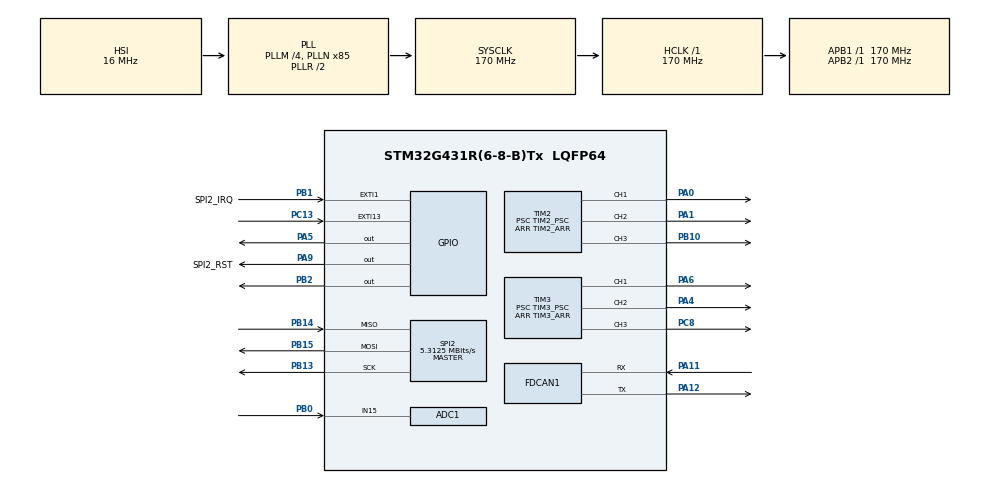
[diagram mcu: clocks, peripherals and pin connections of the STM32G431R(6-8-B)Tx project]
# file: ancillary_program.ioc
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ADC1.Channel-0\#ChannelRegularConversion=ADC_CHANNEL_15
ADC1.ContinuousConvMode=ENABLE
ADC1.EnableInjectedConversion=DISABLE
ADC1.NbrOfConversionFlag=1
ADC1.OffsetNumber-0\#ChannelRegularConversion=ADC_OFFSET_NONE
ADC1.Overrun=ADC_OVR_DATA_OVERWRITTEN
ADC1.Rank-0\#ChannelRegularConversion=1
ADC1.Rank1_Channel=ADC_CHANNEL_15
ADC1.SamplingTime-0\#ChannelRegularConversion=ADC_SAMPLETIME_640CYCLES_5
ADC1.master=1
FDCAN1.CalculateBaudRateNominal=499999
FDCAN1.CalculateTimeBitNominal=2000
FDCAN1.CalculateTimeQuantumNominal=117.64705882352942
FDCAN1.DataPrescaler=2
FDCAN1.DataTimeSeg1=14
FDCAN1.DataTimeSeg2=2
FDCAN1.NominalPrescaler=20
FDCAN1.NominalTimeSeg1=14
FDCAN1.ProtocolException=ENABLE
FDCAN1.StdFiltersNbr=FDCAN_FILTER_COUNT
FDCAN1.TransmitPause=ENABLE
FREERTOS.Tasks01=DefaultTask,24,512,StartDefaultTask,As weak,NULL,Dynamic,NULL,NULL;ArmMotorTask,49,128,StartArmMotorTask,As weak,NULL,Dynamic,NULL,NULL;FdCanTask,41,256,StartFdCanTask,As weak,NULL,Dynamic,NULL,NULL;RfidTask,51,256,StartRfidTask,As weak,NULL,Dynamic,NULL,NULL;MapTask,50,256,StartMapTask,As weak,NULL,Dynamic,NULL,NULL;ArmTask,48,128,StartArmTask,As weak,NULL,Dynamic,NULL,NULL
FREERTOS.configTOTAL_HEAP_SIZE=8192
FREERTOS.configUSE_NEWLIB_REENTRANT=1
Mcu.Family=STM32G4
Mcu.Name=STM32G431R(6-8-B)Tx
Mcu.Package=LQFP64
NUCLEO-G431RB.BUTTON=1
NUCLEO-G431RB.LD1=true
NUCLEO-G431RB.VCP=true
NVIC.EXTI15_10_IRQn=true\:5\:0\:false\:false\:true\:true\:false\:true\:true
NVIC.EXTI1_IRQn=true\:5\:0\:false\:false\:true\:true\:true\:true\:true
NVIC.FDCAN1_IT0_IRQn=true\:5\:0\:false\:false\:true\:true\:true\:true\:true
NVIC.FDCAN1_IT1_IRQn=true\:5\:0\:false\:false\:true\:true\:true\:true\:true
NVIC.PriorityGroup=NVIC_PRIORITYGROUP_4
NVIC.TIM6_DAC_IRQn=true\:15\:0\:false\:false\:true\:false\:false\:true\:true
NVIC.TimeBase=TIM6_DAC_IRQn
NVIC.TimeBaseIP=TIM6
PA0.Signal=S_TIM2_CH1
PA1.Signal=S_TIM2_CH2
PA11.Mode=FDCAN_Activate
PA11.Signal=FDCAN1_RX
PA12.Mode=FDCAN_Activate
PA12.Signal=FDCAN1_TX
PA13.GPIO_Label=T_SWDIO
PA13.Signal=SYS_JTMS-SWDIO
PA14.GPIO_Label=T_SWCLK
PA14.Signal=SYS_JTCK-SWCLK
PA2.Signal=LPUART1_TX
PA3.Signal=LPUART1_RX
PA4.Signal=S_TIM3_CH2
PA5.Signal=GPIO_Output
PA6.Signal=S_TIM3_CH1
PA9.GPIO_Label=SPI2_RST
PA9.Signal=GPIO_Output
PB0.Mode=IN15-Single-Ended
PB0.Signal=ADC1_IN15
PB1.GPIO_Label=SPI2_IRQ
PB1.GPIO_ModeDefaultEXTI=GPIO_MODE_IT_FALLING
PB1.GPIO_PuPd=GPIO_PULLUP
PB1.Signal=GPXTI1
PB10.Signal=S_TIM2_CH3
PB13.Mode=Full_Duplex_Master
PB13.Signal=SPI2_SCK
PB14.Mode=Full_Duplex_Master
PB14.Signal=SPI2_MISO
PB15.Mode=Full_Duplex_Master
PB15.Signal=SPI2_MOSI
PB2.Signal=GPIO_Output
PB3.GPIO_Label=T_SWO
PB3.Signal=SYS_JTDO-SWO
PC13.Signal=GPXTI13
PC14-OSC32_IN.GPIO_Label=RCC_OSC32_OUT
PC14-OSC32_IN.Signal=RCC_OSC32_IN
PC15-OSC32_OUT.GPIO_Label=RCC_OSC32_OUT
PC15-OSC32_OUT.Signal=RCC_OSC32_OUT
PC8.Signal=S_TIM3_CH3
PF0-OSC_IN.GPIO_Label=RCC_OSC_IN
PF0-OSC_IN.Signal=RCC_OSC_IN
PF1-OSC_OUT.GPIO_Label=RCC_OSC_OUT
PF1-OSC_OUT.Signal=RCC_OSC_OUT
ProjectManager.HeapSize=0x200
ProjectManager.StackSize=0x400
ProjectManager.TargetToolchain=STM32CubeIDE
RCC.ADC12Freq_Value=170000000
RCC.AHBFreq_Value=170000000
RCC.APB1Freq_Value=170000000
RCC.APB1TimFreq_Value=170000000
RCC.APB2Freq_Value=170000000
RCC.APB2TimFreq_Value=170000000
RCC.CortexFreq_Value=170000000
RCC.EXTERNAL_CLOCK_VALUE=12288000
RCC.HCLKFreq_Value=170000000
RCC.HSE_VALUE=24000000
RCC.HSI48_VALUE=48000000
RCC.HSI_VALUE=16000000
RCC.LSE_VALUE=32768
RCC.PLLM=RCC_PLLM_DIV4
RCC.PLLN=85
RCC.RTCClockSelection=RCC_RTCCLKSOURCE_LSE
RCC.SYSCLKFreq_VALUE=170000000
RCC.SYSCLKSource=RCC_SYSCLKSOURCE_PLLCLK
RCC.USBFreq_Value=170000000
RCC.VCOOutputFreq_Value=340000000
SH.S_TIM2_CH1.0=TIM2_CH1,PWM Generation1 CH1
SH.S_TIM2_CH2.0=TIM2_CH2,PWM Generation2 CH2
SH.S_TIM2_CH3.0=TIM2_CH3,PWM Generation3 CH3
SH.S_TIM3_CH1.0=TIM3_CH1,PWM Generation1 CH1
SH.S_TIM3_CH2.0=TIM3_CH2,PWM Generation2 CH2
SH.S_TIM3_CH3.0=TIM3_CH3,PWM Generation3 CH3
SPI2.BaudRatePrescaler=SPI_BAUDRATEPRESCALER_32
SPI2.CalculateBaudRate=5.3125 MBits/s
SPI2.DataSize=SPI_DATASIZE_8BIT
SPI2.Direction=SPI_DIRECTION_2LINES
SPI2.Mode=SPI_MODE_MASTER
SPI2.VirtualType=VM_MASTER
TIM2.Channel-PWM\ Generation1\ CH1=TIM_CHANNEL_1
TIM2.Channel-PWM\ Generation2\ CH2=TIM_CHANNEL_2
TIM2.Channel-PWM\ Generation3\ CH3=TIM_CHANNEL_3
TIM2.PeriodNoDither=TIM2_ARR
TIM2.Prescaler=TIM2_PSC
TIM3.Channel-PWM\ Generation1\ CH1=TIM_CHANNEL_1
TIM3.Channel-PWM\ Generation2\ CH2=TIM_CHANNEL_2
TIM3.Channel-PWM\ Generation3\ CH3=TIM_CHANNEL_3
TIM3.PeriodNoDither=TIM3_ARR
TIM3.Prescaler=TIM3_PSC
VP_FREERTOS_VS_CMSIS_V2.Mode=CMSIS_V2
VP_NUCLEO-G431RB_VS_BSP_COMMON.Mode=COMMON
VP_SYS_VS_DBSignals.Mode=DisableDeadBatterySignals
VP_SYS_VS_tim6.Mode=TIM6
board=NUCLEO-G431RB

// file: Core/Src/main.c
/* USER CODE BEGIN Header */
/**
  ******************************************************************************
  * @file           : main.c
  * @brief          : Main program body
  ******************************************************************************
  * @attention
  *
  * Copyright (c) 2025 STMicroelectronics.
  * All rights reserved.
  *
  * This software is licensed under terms that can be found in the LICENSE file
  * in the root directory of this software component.
  * If no LICENSE file comes with this software, it is provided AS-IS.
  *
  ******************************************************************************
  */
/* USER CODE END Header */
#include "main.h"
#include "cmsis_os.h"
#include "adc.h"
#include "fdcan.h"
#include "spi.h"
#include "tim.h"
#include "gpio.h"

COM_InitTypeDef BspCOMInit;

void SystemClock_Config(void);
void MX_FREERTOS_Init(void);

/* USER CODE BEGIN 0 */
uint32_t pulse = 0;
/* USER CODE END 0 */

int main(void)
{

  /* MCU Configuration--------------------------------------------------------*/

  /* Reset of all peripherals, Initializes the Flash interface and the Systick. */
  HAL_Init();

  /* Configure the system clock */
  SystemClock_Config();

  /* Initialize all configured peripherals */
  MX_GPIO_Init();
  MX_TIM2_Init();
  MX_TIM3_Init();
  MX_FDCAN1_Init();
  MX_SPI2_Init();
  MX_ADC1_Init();

  /* Init scheduler */
  osKernelInitialize();

  /* Call init function for freertos objects (in cmsis_os2.c) */
  MX_FREERTOS_Init();

  /* Initialize leds */
  BSP_LED_Init(LED_GREEN);

  /* Initialize USER push-button, will be used to trigger an interrupt each time it's pressed.*/
  BSP_PB_Init(BUTTON_USER, BUTTON_MODE_EXTI);

  /* Initialize COM1 port (115200, 8 bits (7-bit data + 1 stop bit), no parity */
  BspCOMInit.BaudRate   = 115200;
  BspCOMInit.WordLength = COM_WORDLENGTH_8B;
  BspCOMInit.StopBits   = COM_STOPBITS_1;
  BspCOMInit.Parity     = COM_PARITY_NONE;
  BspCOMInit.HwFlowCtl  = COM_HWCONTROL_NONE;
  if (BSP_COM_Init(COM1, &BspCOMInit) != BSP_ERROR_NONE)
  {
    Error_Handler();
  }

  /* Start scheduler */
  osKernelStart();

  /* We should never get here as control is now taken by the scheduler */

  /* Infinite loop */
  while (1)
  {

  }
}

void SystemClock_Config(void)
{
  RCC_OscInitTypeDef RCC_OscInitStruct = {0};
  RCC_ClkInitTypeDef RCC_ClkInitStruct = {0};

  /** Configure the main internal regulator output voltage
  */
  HAL_PWREx_ControlVoltageScaling(PWR_REGULATOR_VOLTAGE_SCALE1_BOOST);

  /** Initializes the RCC Oscillators according to the specified parameters
  * in the RCC_OscInitTypeDef structure.
  */
  RCC_OscInitStruct.OscillatorType = RCC_OSCILLATORTYPE_HSI;
  RCC_OscInitStruct.HSIState = RCC_HSI_ON;
  RCC_OscInitStruct.HSICalibrationValue = RCC_HSICALIBRATION_DEFAULT;
  RCC_OscInitStruct.PLL.PLLState = RCC_PLL_ON;
  RCC_OscInitStruct.PLL.PLLSource = RCC_PLLSOURCE_HSI;
  RCC_OscInitStruct.PLL.PLLM = RCC_PLLM_DIV4;
  RCC_OscInitStruct.PLL.PLLN = 85;
  RCC_OscInitStruct.PLL.PLLP = RCC_PLLP_DIV2;
  RCC_OscInitStruct.PLL.PLLQ = RCC_PLLQ_DIV2;
  RCC_OscInitStruct.PLL.PLLR = RCC_PLLR_DIV2;
  if (HAL_RCC_OscConfig(&RCC_OscInitStruct) != HAL_OK)
  {
    Error_Handler();
  }

  /** Initializes the CPU, AHB and APB buses clocks
  */
  RCC_ClkInitStruct.ClockType = RCC_CLOCKTYPE_HCLK|RCC_CLOCKTYPE_SYSCLK
                              |RCC_CLOCKTYPE_PCLK1|RCC_CLOCKTYPE_PCLK2;
  RCC_ClkInitStruct.SYSCLKSource = RCC_SYSCLKSOURCE_PLLCLK;
  RCC_ClkInitStruct.AHBCLKDivider = RCC_SYSCLK_DIV1;
  RCC_ClkInitStruct.APB1CLKDivider = RCC_HCLK_DIV1;
  RCC_ClkInitStruct.APB2CLKDivider = RCC_HCLK_DIV1;

  if (HAL_RCC_ClockConfig(&RCC_ClkInitStruct, FLASH_LATENCY_4) != HAL_OK)
  {
    Error_Handler();
  }
}

void HAL_TIM_PeriodElapsedCallback(TIM_HandleTypeDef *htim)
{
  if (htim->Instance == TIM6) {
    HAL_IncTick();
  }
}

void Error_Handler(void)
{
  __disable_irq();
  while (1)
  {
  }
}

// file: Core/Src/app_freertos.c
/* USER CODE BEGIN Header */
/**
  ******************************************************************************
  * File Name          : app_freertos.c
  * Description        : Code for freertos applications
  ******************************************************************************
  * @attention
  *
  * Copyright (c) 2025 STMicroelectronics.
  * All rights reserved.
  *
  * This software is licensed under terms that can be found in the LICENSE file
  * in the root directory of this software component.
  * If no LICENSE file comes with this software, it is provided AS-IS.
  *
  ******************************************************************************
  */
/* USER CODE END Header */

#include "FreeRTOS.h"
#include "task.h"
#include "main.h"
#include "cmsis_os.h"

/* Definitions for DefaultTask */
osThreadId_t DefaultTaskHandle;
const osThreadAttr_t DefaultTask_attributes = {
  .name = "DefaultTask",
  .priority = (osPriority_t) osPriorityNormal,
  .stack_size = 512 * 4
};
/* Definitions for ArmMotorTask */
osThreadId_t ArmMotorTaskHandle;
const osThreadAttr_t ArmMotorTask_attributes = {
  .name = "ArmMotorTask",
  .priority = (osPriority_t) osPriorityRealtime1,
  .stack_size = 128 * 4
};
/* Definitions for FdCanTask */
osThreadId_t FdCanTaskHandle;
const osThreadAttr_t FdCanTask_attributes = {
  .name = "FdCanTask",
  .priority = (osPriority_t) osPriorityHigh1,
  .stack_size = 256 * 4
};
/* Definitions for RfidTask */
osThreadId_t RfidTaskHandle;
const osThreadAttr_t RfidTask_attributes = {
  .name = "RfidTask",
  .priority = (osPriority_t) osPriorityRealtime3,
  .stack_size = 256 * 4
};
/* Definitions for MapTask */
osThreadId_t MapTaskHandle;
const osThreadAttr_t MapTask_attributes = {
  .name = "MapTask",
  .priority = (osPriority_t) osPriorityRealtime2,
  .stack_size = 256 * 4
};
/* Definitions for ArmTask */
osThreadId_t ArmTaskHandle;
const osThreadAttr_t ArmTask_attributes = {
  .name = "ArmTask",
  .priority = (osPriority_t) osPriorityRealtime,
  .stack_size = 128 * 4
};

void StartDefaultTask(void *argument);
void StartArmMotorTask(void *argument);
void StartFdCanTask(void *argument);
void StartRfidTask(void *argument);
void StartMapTask(void *argument);
void StartArmTask(void *argument);

void MX_FREERTOS_Init(void); /* (MISRA C 2004 rule 8.1) */

void MX_FREERTOS_Init(void) {

  /* Create the thread(s) */
  /* creation of DefaultTask */
  DefaultTaskHandle = osThreadNew(StartDefaultTask, NULL, &DefaultTask_attributes);

  /* creation of ArmMotorTask */
  ArmMotorTaskHandle = osThreadNew(StartArmMotorTask, NULL, &ArmMotorTask_attributes);

  /* creation of FdCanTask */
  FdCanTaskHandle = osThreadNew(StartFdCanTask, NULL, &FdCanTask_attributes);

  /* creation of RfidTask */
  RfidTaskHandle = osThreadNew(StartRfidTask, NULL, &RfidTask_attributes);

  /* creation of MapTask */
  MapTaskHandle = osThreadNew(StartMapTask, NULL, &MapTask_attributes);

  /* creation of ArmTask */
  ArmTaskHandle = osThreadNew(StartArmTask, NULL, &ArmTask_attributes);

}

__weak void StartDefaultTask(void *argument)
{
  for(;;)
  {
    osDelay(1);
  }
}

__weak void StartArmMotorTask(void *argument)
{
  for(;;)
  {
    osDelay(1);
  }
}

__weak void StartFdCanTask(void *argument)
{
  for(;;)
  {
    osDelay(1);
  }
}

__weak void StartRfidTask(void *argument)
{
  for(;;)
  {
    osDelay(1);
  }
}

__weak void StartMapTask(void *argument)
{
  for(;;)
  {
    osDelay(1);
  }
}

__weak void StartArmTask(void *argument)
{
  for(;;)
  {
    osDelay(1);
  }
}
